# MAX32550 register map
Vendor: Maxim Integrated; File version: 1.0
Registers are 32-bit, read-write, reset 0x0 unless marked. A register's access mark holds for its fields unless they carry their own. Offsets are from the block's base; [hi:lo] are bit positions; {n}, {i} and the like mark numbered series.

## SecureKeyboard
Base 0x40032000; register names take the prefix KBD_
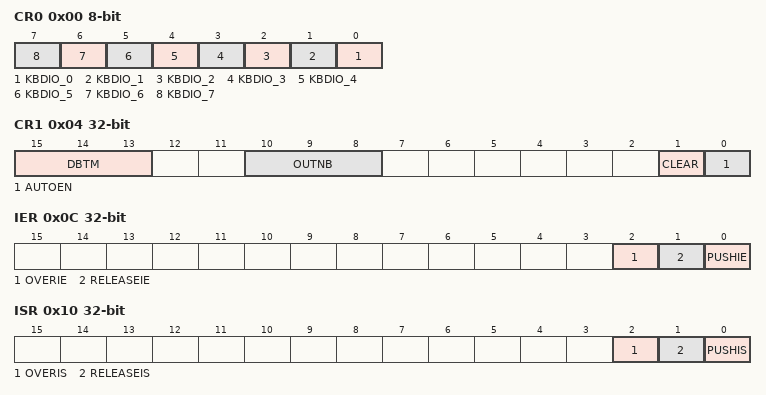
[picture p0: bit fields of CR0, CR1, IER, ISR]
0x00 CR0 8-bit — Input Output Select Bits. Each bit of IOSEL selects the pin direction for the corresponding KBDIO pin. If IOSEL[0] = 1, KBDIO0 is an output.
  [all] fields
    0=input; 1=output
  [n] KBDIO_{n} (n=0..7) — Input Output Select for KBDIO{n} pin.
0x04 CR1 — Control Register 1
  [15:13] DBTM — Debounce Time. Number of milliseconds a keypress event must be active before it is considered actual. NOTE: Debounce time values based on system running from an external 12MHz clock source with PLL0 enabled. Other external crystal values will cause the debounce time to scale linearly.
    0=time4ms (4.1 ms); 1=time5ms (5.3 ms); 2=time6ms (6.5 ms); 3=time7ms (7.6 ms); 4=time8ms (8.8 ms); 5=time10ms (10.0 ms); 6=time11ms (11.2 ms); 7=time12ms (12.3 ms)
  [10:8] OUTNB — Output Number. Number of KBDIO pins selected as outputs. NOTE: Output pins must be allocated contiguously starting with KBDIO0 and continuing through to KBDIO7.
  [1] CLEAR — Auto Clear Bit
    0=disable; 1=enable
  [0] AUTOEN — Automatic Keyboard Scan Enable
    0=disable; 1=enable
0x08 SR 1-bit ro — Status Register
  [0] BUSY — Busy bit. This bit is set by hardware when the automatic keyboard scan is enabled and running. This bit is clear at all other times.
    0=idle; 1=busy
0x0C IER — Interrupt Enable Register
  [all] fields
    0=disable; 1=enable
  [2] OVERIE — Overrun Event Enable Bit. When set, this bit enables an interrupt to be generated on an overrun event. Automatic keyboard scan must be enabled.
  [1] RELEASEIE — Release Event Enable Bit. When set, this bit enables an interrupt to be generated on a key release event. Automatic keyboard scan must be enabled.
  [0] PUSHIE — Push Event Enable Bit. When set, this bit enables an interrupt to be generated on a key push event. Automatic keyboard scan must be enabled.
0x10 ISR — Interrupt Status Register
  [all] fields
    0=inactive (No interrupt is pending.); 1=pending (An interrupt is pending.)
  [2] OVERIS — Overrun Event Enable Bit. This bit is set by hardware when an overrun event has occurred. If the interrupt is enabled for this flag, a system interrupt will be fired. If the interrupt enable is not set, the flag will be set, but no interrupt will fire. This bit must be cleared by software.
  [1] RELEASEIS — Release Interrupt Flag. This bit is set by hardware when a key has been released. If the interrupt is enabled for this flag, a system interrupt will be fired. If the interrupt enable is not set, the flag will be set, but no interrupt will fire. This bit must be cleared by software.
  [0] PUSHIS — Push Interrupt Flag. This bit is set by hardware when a key has been pushed. If the interrupt is enabled for this flag, a system interrupt will be fired. If the interrupt enable is not set, the flag will be set, but no interrupt will fire. This bit must be cleared by software.
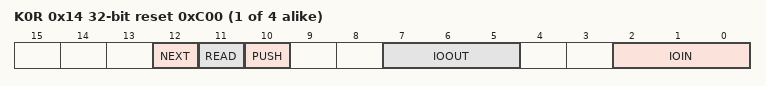
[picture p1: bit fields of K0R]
{0x14+4i} K{i}R (i=0..3) ro reset 0xC00 — Key Register
  [12] NEXT — If set to 1 one of the next key registers (x+1 to 3) contains a key event.
    0=none (No more key register contain a key event.); 1=more (Other key registers contain a key event.)
  [11] READ — If set to 1 this register has been read. If set to 0 the key register has not been read since its last change.
    0=notRead (This register has not been read since its last change.); 1=read (This register has been read.)
  [10] PUSH — If set to 1 the key has been released. If set to 0 the key has been pushed.
    0=pushed; 1=released
  [7:5] IOOUT — IO Output. Output pin of key event.
  [2:0] IOIN — IO Input. Input pin of key event.

## Timer_0 — 32-bit reloadable timer that can be used for timing and event counting.
Base 0x40010000; register names take the prefix TMR0_
Same registers: Timer_1 0x40011000 (register names take the prefix TMR1_), Timer_2 0x40012000 (register names take the prefix TMR2_), Timer_3 0x40013000 (register names take the prefix TMR3_), Timer_4 0x40014000 (register names take the prefix TMR14_), Timer_5 0x40015000 (register names take the prefix TMR5_)
0x00 CNT reset 0x1 — Count. This register stores the current timer count.
0x04 CMP reset 0xFFFF — Compare. This register stores the compare value, which is used to set the maximum count value to initiate a reload of the timer to 0x0001.
0x08 PWM — PWM. This register stores the value that is compared to the current timer count.
0x0C INT 1-bit write-clears — Clear Interrupt. Writing a value (0 or 1) to a bit in this register clears the associated interrupt.
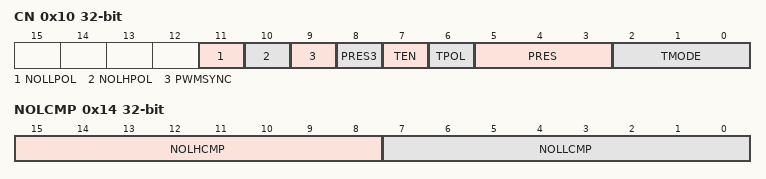
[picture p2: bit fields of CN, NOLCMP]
0x10 CN — Timer Control Register
  [11] NOLLPOL — Timer PWM output 0A' polarity bit.
    0=disable; 1=enable
  [10] NOLHPOL — Timer PWM output 0A polarity bit.
    0=disable; 1=enable
  [9] PWMSYNC — Timer PWM Synchronization Mode Enable
    0=disable; 1=enable
  [8] PRES3 — MSB of prescaler value.
    0=div1; 1=div256
  [7] TEN — Timer Enable
    0=disable; 1=enable
  [6] TPOL — Timer input/output polarity bit
    0=activeHi; 1=activeLo
  [5:3] PRES — Prescaler. The prescaler bits are formed from PRES3:PRES[2:0]
    0=div1; 1=div2; 2=div4; 3=div8; 4=div16; 5=div32; 6=div64; 7=div128
  [2:0] TMODE — Timer Mode
    0=oneShot; 1=continuous; 2=counter; 3=pwm; 4=capture; 5=compare; 6=gated; 7=captureCompare
0x14 NOLCMP — Timer Non-Overlapping Compare Register
  [15:8] NOLHCMP — Non-overlapping High Compare. The 8-bit timer count value of non-overlapping time between falling edge of PWM output 0A' and next rising edge of PWM output 0A.
  [7:0] NOLLCMP — Non-overlapping Low Compare. The 8-bit timer count value of non-overlapping time between falling edge of PWM output 0A and next rising edge of PWM output 0A'.
